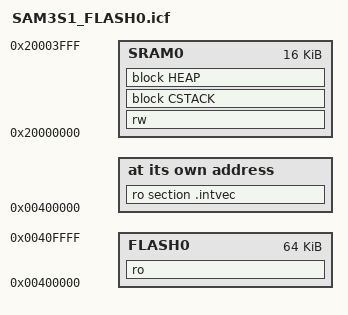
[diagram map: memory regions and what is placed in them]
/*###ICF### Section handled by ICF editor, don't touch! ****/
/*-Editor annotation file-*/
/* IcfEditorFile="$TOOLKIT_DIR$\config\ide\IcfEditor\a_v1_0.xml" */
/*-Specials-*/
define symbol __ICFEDIT_intvec_start__ = 0x00400000;
/*-Memory Regions-*/

define symbol __ICFEDIT_region_FLASH0_start__  = 0x00400000;
define symbol __ICFEDIT_region_FLASH0_size__   = 0x10000;
define symbol __ICFEDIT_region_SRAM0_start__   = 0x20000000;
define symbol __ICFEDIT_region_SRAM0_size__    = 0x4000;
/*-Sizes-*/
define symbol __ICFEDIT_size_cstack__   = 0x1000;
define symbol __ICFEDIT_size_heap__     = 0x800;
/**** End of ICF editor section. ###ICF###*/


define memory mem with size = 4G;
define region FLASH0  = mem:[from __ICFEDIT_region_FLASH0_start__  size __ICFEDIT_region_FLASH0_size__];
define region SRAM0   = mem:[from __ICFEDIT_region_SRAM0_start__   size __ICFEDIT_region_SRAM0_size__];

define block CSTACK    with alignment = 4, size = __ICFEDIT_size_cstack__   { };
define block HEAP      with alignment = 4, size = __ICFEDIT_size_heap__     { };

initialize by copy { rw };
do not initialize  { section .noinit };


place at address mem:__ICFEDIT_intvec_start__ { ro section .intvec };

place in FLASH0  { ro  };
place in SRAM0   { rw , block CSTACK, block HEAP };
                        
